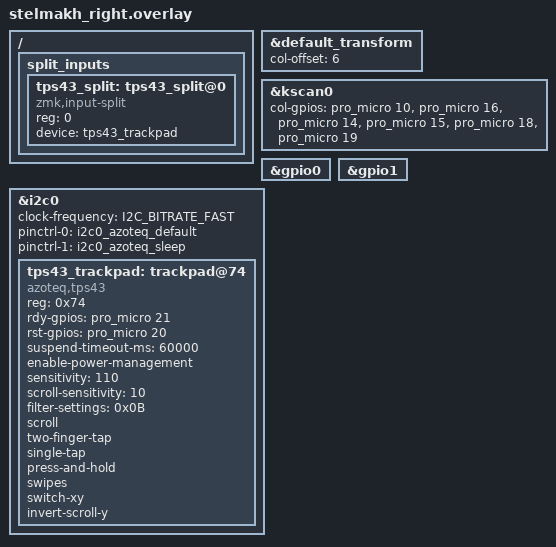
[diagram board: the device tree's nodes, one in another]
#include <zephyr/dt-bindings/i2c/i2c.h>
#include <dt-bindings/pinctrl/nrf-pinctrl.h>
#include <dt-bindings/gpio/gpio.h>

#include "stelmakh.dtsi"
#include "stelmakh-pinctrl.dtsi"

&default_transform {
    col-offset = <6>;
};

&kscan0 {
    col-gpios
        = <&pro_micro 10 GPIO_ACTIVE_HIGH>
        , <&pro_micro 16 GPIO_ACTIVE_HIGH>
        , <&pro_micro 14 GPIO_ACTIVE_HIGH>
        , <&pro_micro 15 GPIO_ACTIVE_HIGH>
        , <&pro_micro 18 GPIO_ACTIVE_HIGH>
        , <&pro_micro 19 GPIO_ACTIVE_HIGH>
        ;
};



// Enable GPIO controllers
&gpio0 {
    status = "okay";
};

&gpio1 {
    status = "okay";
};

&i2c0 {
    status = "okay";
    clock-frequency = <I2C_BITRATE_FAST>;
    pinctrl-0 = <&i2c0_azoteq_default>;
    pinctrl-1 = <&i2c0_azoteq_sleep>;
    pinctrl-names = "default", "sleep";

    tps43_trackpad: trackpad@74 {
        compatible = "azoteq,tps43";
        reg = <0x74>;
        status = "okay";
        
        /* GPIO connections */
        rdy-gpios = <&pro_micro 21 GPIO_ACTIVE_HIGH>;  /* Ready pin */
        rst-gpios = <&pro_micro 20 GPIO_ACTIVE_HIGH>;  /* Reset pin */

        suspend-timeout-ms = <60000>;  /* 60 seconds */
        enable-power-management;
        
        /* Gesture settings */
        sensitivity = <110>;           /* 100% = normal */
        scroll-sensitivity = <10>;     /* 50% = normal */

        filter-settings=<0x0B>;

        scroll;
        two-finger-tap;
        single-tap;
        press-and-hold;
        swipes;

        switch-xy;
        invert-scroll-y;
    };
};

/ {
    split_inputs {
        #address-cells = <1>;
        #size-cells = <0>;

        tps43_split: tps43_split@0 {
            compatible = "zmk,input-split";
            reg = <0>;
            device = <&tps43_trackpad>;
        };
    };
};
